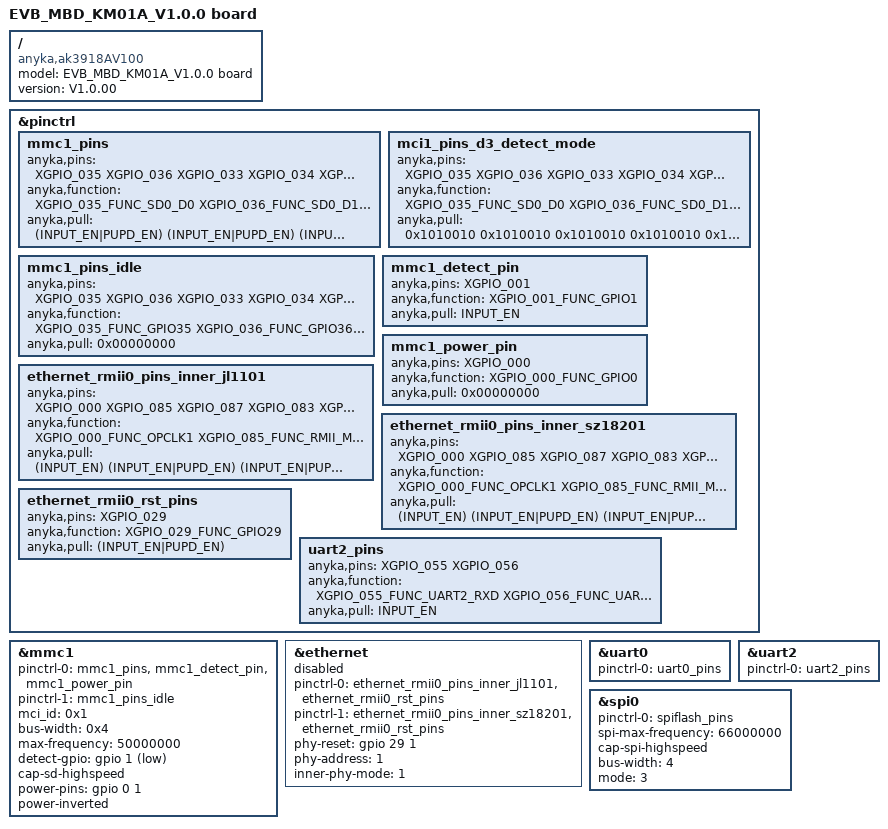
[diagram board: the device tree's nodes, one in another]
/*
 * Anycloud37e develop board dts
 *
 * Copyright (C) 2020 Anyka(Guangzhou) Microelectronics Technology Co., Ltd.
 *
 * This program is free software; you can redistribute it and/or modify
 * it under the terms of the GNU General Public License as published by
 * the Free Software Foundation; either version 2 of the License, or
 * (at your option) any later version.
 *
 * This program is distributed in the hope that it will be useful,
 * but WITHOUT ANY WARRANTY; without even the implied warranty of
 * MERCHANTABILITY or FITNESS FOR A PARTICULAR PURPOSE.  See the
 * GNU General Public License for more details.
 */

/dts-v1/;
#include "anycloud_km01a_common.dtsi"
#include "anycloud_km01a_pinctrl.dtsi"

/ {
    compatible = "anyka,ak3918AV100";
    model = "EVB_MBD_KM01A_V1.0.0  board";
    version = "V1.0.00";
};

&pinctrl {
    /*
    * "anyka,function": func index, please refer to dt-bindings/pinctrl/ak_3918av100_pinctrl.h
    * "anyka,pull": configuration of the pins
    * bit[7:0]: pull up/down configuration
    *     bit[0]: pull up or pull down selection, 1 means select pull down, 0 means select pull up
    *     bit[4]: pull up or pull down enable, 1 means enable pull up&down function, 0 means disable fuction
    * !!! Notice that not all pin support pull up and pull down. Please refer to the programer's guide.
    * bit[15:8]: driver strength configuration.
    *     bit[9:8] drive strength.
    * bit[23:16]: input enable configuration
    *     bit[16]: 1 means enable input, 0 means disable input.
    * bit[31:24]: pin slew rate configuration
    *     bit[24]: 1 means enable slew rate, 0 means disable slew rate.
    * !!! Notice OTHER bits which not mentioned please set to 0.
    */

    mmc1_pins: mmc1_pins {
        anyka,pins = <XGPIO_035 XGPIO_036 XGPIO_033 XGPIO_034 XGPIO_031 XGPIO_032>;
        anyka,function = <XGPIO_035_FUNC_SD0_D0
                            XGPIO_036_FUNC_SD0_D1
                            XGPIO_033_FUNC_SD0_CMD
                            XGPIO_034_FUNC_SD0_MCLK
                            XGPIO_031_FUNC_SD0_D2
                            XGPIO_032_FUNC_SD0_D3>;

        anyka,pull = <(INPUT_EN|PUPD_EN)
						(INPUT_EN|PUPD_EN)
						(INPUT_EN|PUPD_EN)
						(INPUT_EN|PULL_DOWN)
						(INPUT_EN|PUPD_EN)
						(INPUT_EN|PUPD_EN)
						>;
    };

	/* 
     *  When using DATA3 as plugin and plugoff detect:
     *  1. Set XGPIO_032_FUNC_SDIO0_DATA3 pull up disable and pull down disable
     *  2. Using PULLDOWN RESISTANCE on PCB, for example, 510K.
    */      
    mci1_pins_d3_detect_mode: mci1_pins_d3_detect_mode {
        anyka,pins = <XGPIO_035 XGPIO_036 XGPIO_033 XGPIO_034 XGPIO_031 XGPIO_032>;
        anyka,function = <XGPIO_035_FUNC_SD0_D0
                            XGPIO_036_FUNC_SD0_D1
                            XGPIO_033_FUNC_SD0_CMD
                            XGPIO_034_FUNC_SD0_MCLK
                            XGPIO_031_FUNC_SD0_D2
                            XGPIO_032_FUNC_SD0_D3>;
        anyka,pull = <  0x1010010 
                        0x1010010
                        0x1010010
                        0x1010010  
                        0x1010010
                        0x1010001>;/* disable pull down and pull up */
    };
    
    mmc1_pins_idle: mmc1_pins_idle {
        anyka,pins = <XGPIO_035 XGPIO_036 XGPIO_033 XGPIO_034 XGPIO_031 XGPIO_032>;
        anyka,function = <XGPIO_035_FUNC_GPIO35
                            XGPIO_036_FUNC_GPIO36
                            XGPIO_033_FUNC_GPIO33
                            XGPIO_034_FUNC_GPIO34
                            XGPIO_031_FUNC_GPIO31
                            XGPIO_032_FUNC_GPIO32>;
        anyka,pull = <0x00000000>;
    };

	//EVB_CBDM_AK3918AV100N or EVB_CBDM_AK3918AV100P
	mmc1_detect_pin: mmc1_detect_pin {
        anyka,pins = <XGPIO_001>;
        anyka,function = <XGPIO_001_FUNC_GPIO1>;
        anyka,pull = <INPUT_EN>;
    };
    
    mmc1_power_pin: mmc1_power_pin {
        anyka,pins = <XGPIO_000>;
        anyka,function = <XGPIO_000_FUNC_GPIO0>;
        anyka,pull = <0x00000000>;
    };

    ethernet_rmii0_pins_inner_jl1101: ethernet_rmii0_pins_inner_jl1101 {
        anyka,pins = <XGPIO_000
                        XGPIO_085
                        XGPIO_087
                        XGPIO_083
                        XGPIO_084
                        XGPIO_091
                        XGPIO_088
                        XGPIO_082
                        XGPIO_089
                        XGPIO_090
                        XGPIO_086
						XGPIO_028>;
        anyka,function = <XGPIO_000_FUNC_OPCLK1
                            XGPIO_085_FUNC_RMII_MDIO
							XGPIO_087_FUNC_RMII_MDC
                            XGPIO_083_FUNC_RMII_RXER
                            XGPIO_084_FUNC_RMII_RXDV
                            XGPIO_091_FUNC_RMII_RXD0
                            XGPIO_088_FUNC_RMII_RXD1
                            XGPIO_082_FUNC_GPIO82
                            XGPIO_089_FUNC_RMII_TXD0
                            XGPIO_090_FUNC_RMII_TXD1
                            XGPIO_086_FUNC_RMII_TXEN
							XGPIO_028_FUNC_MAC_PHY_25M>;
        anyka,pull = <(INPUT_EN)
                        (INPUT_EN|PUPD_EN)
                        (INPUT_EN|PUPD_EN|PULL_DOWN)
                        (INPUT_EN|PUPD_EN|PULL_DOWN)
                        (INPUT_EN|PUPD_EN|PULL_DOWN)
                        (INPUT_EN|PUPD_EN|PULL_DOWN)
                        (INPUT_EN|PUPD_EN|PULL_DOWN)
                        (INPUT_EN|GPIO_DIR_EN|GPIO_DIR_IN)
                        (FAST_CTRL|INPUT_EN|PUPD_EN|PULL_DOWN)
                        (FAST_CTRL|INPUT_EN|PUPD_EN|PULL_DOWN)
                        (INPUT_EN|PUPD_EN|PULL_DOWN)
                        (INPUT_EN|PUPD_EN)>;
	};

    ethernet_rmii0_pins_inner_sz18201: ethernet_rmii0_pins_inner_sz18201 {
        anyka,pins = <XGPIO_000
                        XGPIO_085
                        XGPIO_087
                        XGPIO_083
                        XGPIO_084
                        XGPIO_091
                        XGPIO_088
                        XGPIO_082
                        XGPIO_089
                        XGPIO_090
                        XGPIO_086
						XGPIO_028>;
        anyka,function = <XGPIO_000_FUNC_OPCLK1
                            XGPIO_085_FUNC_RMII_MDIO
							XGPIO_087_FUNC_RMII_MDC
                            XGPIO_083_FUNC_RMII_RXER
                            XGPIO_084_FUNC_RMII_RXDV
                            XGPIO_091_FUNC_RMII_RXD0
                            XGPIO_088_FUNC_RMII_RXD1
                            XGPIO_082_FUNC_GPIO82
                            XGPIO_089_FUNC_RMII_TXD0
                            XGPIO_090_FUNC_RMII_TXD1
                            XGPIO_086_FUNC_RMII_TXEN
							XGPIO_028_FUNC_MAC_PHY_25M>;
        anyka,pull = <(INPUT_EN)
                        (INPUT_EN|PUPD_EN)
                        (INPUT_EN|PUPD_EN|PULL_DOWN)
                        (INPUT_EN|PUPD_EN|PULL_DOWN)
                        (INPUT_EN|PUPD_EN|PULL_DOWN)
                        (INPUT_EN|PUPD_EN|PULL_DOWN)
                        (INPUT_EN|PUPD_EN|PULL_DOWN)
                        (INPUT_EN|GPIO_DIR_EN|GPIO_DIR_IN)
                        (FAST_CTRL|INPUT_EN|PUPD_EN|PULL_DOWN)
                        (FAST_CTRL|INPUT_EN|PUPD_EN|PULL_DOWN)
                        (INPUT_EN|PUPD_EN|PULL_DOWN)
                        (INPUT_EN|PUPD_EN)>;
	};

    ethernet_rmii0_rst_pins: ethernet_rmii0_rst_pins {
        anyka,pins = <XGPIO_029>;
        anyka,function = <XGPIO_029_FUNC_GPIO29>;
        anyka,pull = <(INPUT_EN|PUPD_EN)>;
    };

    uart2_pins: uart2_pins {
        anyka,pins = <XGPIO_055 XGPIO_056>;
        anyka,function = <XGPIO_055_FUNC_UART2_RXD XGPIO_056_FUNC_UART2_TXD>;
        anyka,pull = <INPUT_EN>;
    };
};

    /*
     *  detect mode:
     *  (1) non-removable;
     *  (2) detect-gpio/detect-gpios: card detect using gpio
     *      for example:
     *      detect-gpio = <&gpio 76 1>;  or detect-gpios = <&gpio 76 1>;
     *  (3) cd_clk: card detect using MCLK
	 *  (4) cd_d3: card detect using DATA3
     */
/* mmc1 card detect using  detect-gpio*/

&mmc1 {
    pinctrl-names = "default","idle";
    pinctrl-0 = <&mmc1_pins &mmc1_detect_pin &mmc1_power_pin>;
    pinctrl-1 = <&mmc1_pins_idle>;

	mci_id = <0x1>;  //for mmc id
    bus-width = <0x4>;
    max-frequency = <50000000>;
    detect-gpio = <&gpio 1 1>; //EVB_CBDM_AK3918AV100P
    // if support highspeed, using cap-sd-highspeed
    cap-sd-highspeed; 
    //support tf card circuit enable function 
    power-pins = <&gpio 0 1>;      //power-pins is which tf_en_pins describes
    power-inverted;
    status = "okay";
};

/* mmc1 card detect using  cd_clk*/
/*
&mmc1 {
    pinctrl-names = "default","idle";
    //pinctrl-0 = <&mmc1_pins &mmc1_detect_pin &mmc1_power_pin>;
    pinctrl-0 = <&mmc1_pins &mmc1_power_pin>;
    pinctrl-1 = <&mmc1_pins_idle>;

	mci_id = <0x1>;  //for mmc id
    bus-width = <0x4>;
    max-frequency = <50000000>;
    cd_clk;
    // if support highspeed, using cap-sd-highspeed
    cap-sd-highspeed; 
    //support tf card circuit enable function 
    power-pins = <&gpio 0 1>;      //power-pins is which tf_en_pins describes
    power-inverted;
    status = "okay";
};
*/

/* mmc1 card detect using cd_d3 */
/*
&mmc1 {
    pinctrl-names = "default","idle";
    pinctrl-0 = <&mci1_pins_d3_detect_mode &mmc1_power_pin>;
    pinctrl-1 = <&mmc1_pins_idle>;

	mci_id = <0x1>;  //for mmc id
    bus-width = <0x4>;
    max-frequency = <50000000>;

    cd_d3;
    // if support highspeed, using cap-sd-highspeed 
    cap-sd-highspeed; 
    //support tf card circuit enable function    
    power-pins = <&gpio 0 1>;      //power-pins is which tf_en_pins describes
    power-inverted;
    status = "okay";
};
*/
    

&ethernet {
    pinctrl-names = "default", "inner_sz18201";
	pinctrl-0 = <&ethernet_rmii0_pins_inner_jl1101 &ethernet_rmii0_rst_pins>;
	pinctrl-1 = <&ethernet_rmii0_pins_inner_sz18201 &ethernet_rmii0_rst_pins>;
    phy-reset = <&gpio 29 1>; //EVB_CBDM_SVT or EVB_CBDM_AK3918AV100P
    //phy-reset = <&gpio 24 1>;//EVB_CBDM_AK3918AV100N
	phy-address = <1>;
    inner-phy-mode = <1>;

	status = "disable";
	    
};

&uart0 {
    pinctrl-names = "default";
    pinctrl-0 = <&uart0_pins>;
    status = "okay";
};

&uart2 {
    pinctrl-names = "default";
    pinctrl-0 = <&uart2_pins>;
    status = "okay";
};

&spi0 {
    pinctrl-names = "default";
    pinctrl-0 = <&spiflash_pins>;
     /*pinctrl-names = "default";*/
     /*pinctrl-0 = <&spiflash_pins>;*/
    spi-max-frequency = <66000000>;
    /*
     * cap-spi-highspeed;
     * if defined, means high speed controller(Maximum 80M/s);
     * if not, means normal speed controller(below 60M/s)
     */
    cap-spi-highspeed;
    /* spi flash data bus width:
        ** 1 means 1 wire mode.
        ** 2 means 2 wire mode
        ** 4 means 4 wire mode.
        ** default: 4 wire mode.
        **/
    bus-width = <4>;
    mode = <3>; /* spi mode selected  */  
    status = "okay";
};

